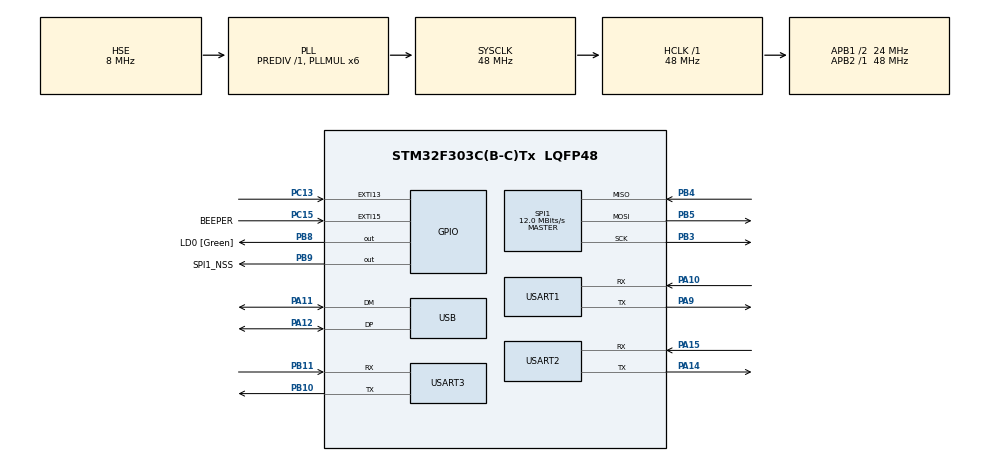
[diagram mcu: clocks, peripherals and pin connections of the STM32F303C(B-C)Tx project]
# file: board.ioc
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Mcu.Family=STM32F3
Mcu.Name=STM32F303C(B-C)Tx
Mcu.Package=LQFP48
NVIC.PriorityGroup=NVIC_PRIORITYGROUP_4
NVIC.USB_LP_CAN_RX0_IRQn=true\:0\:0\:false\:false\:true\:false
PA0.Signal=S_TIM2_CH1_ETR
PA1.Signal=S_TIM2_CH2
PA10.Mode=Asynchronous
PA10.Signal=USART1_RX
PA11.Mode=Device
PA11.Signal=USB_DM
PA12.Mode=Device
PA12.Signal=USB_DP
PA14.Mode=Asynchronous
PA14.Signal=USART2_TX
PA15.Mode=Asynchronous
PA15.Signal=USART2_RX
PA2.Signal=S_TIM2_CH3
PA3.Signal=S_TIM2_CH4
PA9.Mode=Asynchronous
PA9.Signal=USART1_TX
PB10.Mode=Asynchronous
PB10.Signal=USART3_TX
PB11.Mode=Asynchronous
PB11.Signal=USART3_RX
PB3.Mode=Full_Duplex_Master
PB3.Signal=SPI1_SCK
PB4.Mode=Full_Duplex_Master
PB4.Signal=SPI1_MISO
PB5.Mode=Full_Duplex_Master
PB5.Signal=SPI1_MOSI
PB8.GPIO_Label=LD0 [Green]
PB8.Signal=GPIO_Output
PB9.GPIO_Label=SPI1_NSS
PB9.Signal=GPIO_Output
PC13.Signal=GPXTI13
PC15-OSC32_OUT.GPIO_Label=BEEPER
PC15-OSC32_OUT.Signal=GPXTI15
PF0-OSC_IN.Mode=HSE-External-Oscillator
PF0-OSC_IN.Signal=RCC_OSC_IN
PF1-OSC_OUT.Mode=HSE-External-Oscillator
PF1-OSC_OUT.Signal=RCC_OSC_OUT
ProjectManager.HeapSize=0x200
ProjectManager.StackSize=0x400
ProjectManager.TargetToolchain=Makefile
RCC.AHBFreq_Value=48000000
RCC.APB1CLKDivider=RCC_HCLK_DIV2
RCC.APB1Freq_Value=24000000
RCC.APB1TimFreq_Value=48000000
RCC.APB2Freq_Value=48000000
RCC.APB2TimFreq_Value=48000000
RCC.CortexFreq_Value=48000000
RCC.HCLKFreq_Value=48000000
RCC.HSE_VALUE=8000000
RCC.HSI_VALUE=8000000
RCC.LSE_VALUE=32768
RCC.PLLMUL=RCC_PLL_MUL6
RCC.SYSCLKFreq_VALUE=48000000
RCC.SYSCLKSourceVirtual=RCC_SYSCLKSOURCE_PLLCLK
RCC.USBFreq_Value=48000000
SH.S_TIM2_CH1_ETR.0=TIM2_CH1
SH.S_TIM2_CH2.0=TIM2_CH2
SH.S_TIM2_CH3.0=TIM2_CH3
SH.S_TIM2_CH4.0=TIM2_CH4
SPI1.BaudRatePrescaler=SPI_BAUDRATEPRESCALER_4
SPI1.CalculateBaudRate=12.0 MBits/s
SPI1.Direction=SPI_DIRECTION_2LINES
SPI1.Mode=SPI_MODE_MASTER
SPI1.VirtualType=VM_MASTER
USART1.VirtualMode-Asynchronous=VM_ASYNC
USART2.VirtualMode-Asynchronous=VM_ASYNC
USART3.VirtualMode-Asynchronous=VM_ASYNC
USB_DEVICE.CLASS_NAME_FS=CDC
USB_DEVICE.VirtualMode=Cdc
USB_DEVICE.VirtualModeFS=Cdc_FS
VP_USB_DEVICE_VS_USB_DEVICE_CDC_FS.Mode=CDC_FS
board=board

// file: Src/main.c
/**
  ******************************************************************************
  * File Name          : main.c
  * Description        : Main program body
  ******************************************************************************
  * This notice applies to any and all portions of this file
  * that are not between comment pairs USER CODE BEGIN and
  * USER CODE END. Other portions of this file, whether
  * inserted by the user or by software development tools
  * are owned by their respective copyright owners.
  *
  * Copyright (c) 2018 STMicroelectronics International N.V.
  * All rights reserved.
  *
  * Redistribution and use in source and binary forms, with or without
  * modification, are permitted, provided that the following conditions are met:
  *
  * 1. Redistribution of source code must retain the above copyright notice,
  *    this list of conditions and the following disclaimer.
  * 2. Redistributions in binary form must reproduce the above copyright notice,
  *    this list of conditions and the following disclaimer in the documentation
  *    and/or other materials provided with the distribution.
  * 3. Neither the name of STMicroelectronics nor the names of other
  *    contributors to this software may be used to endorse or promote products
  *    derived from this software without specific written permission.
  * 4. This software, including modifications and/or derivative works of this
  *    software, must execute solely and exclusively on microcontroller or
  *    microprocessor devices manufactured by or for STMicroelectronics.
  * 5. Redistribution and use of this software other than as permitted under
  *    this license is void and will automatically terminate your rights under
  *    this license.
  *
  * THIS SOFTWARE IS PROVIDED BY STMICROELECTRONICS AND CONTRIBUTORS "AS IS"
  * AND ANY EXPRESS, IMPLIED OR STATUTORY WARRANTIES, INCLUDING, BUT NOT
  * LIMITED TO, THE IMPLIED WARRANTIES OF MERCHANTABILITY, FITNESS FOR A
  * PARTICULAR PURPOSE AND NON-INFRINGEMENT OF THIRD PARTY INTELLECTUAL PROPERTY
  * RIGHTS ARE DISCLAIMED TO THE FULLEST EXTENT PERMITTED BY LAW. IN NO EVENT
  * SHALL STMICROELECTRONICS OR CONTRIBUTORS BE LIABLE FOR ANY DIRECT, INDIRECT,
  * INCIDENTAL, SPECIAL, EXEMPLARY, OR CONSEQUENTIAL DAMAGES (INCLUDING, BUT NOT
  * LIMITED TO, PROCUREMENT OF SUBSTITUTE GOODS OR SERVICES; LOSS OF USE, DATA,
  * OR PROFITS; OR BUSINESS INTERRUPTION) HOWEVER CAUSED AND ON ANY THEORY OF
  * LIABILITY, WHETHER IN CONTRACT, STRICT LIABILITY, OR TORT (INCLUDING
  * NEGLIGENCE OR OTHERWISE) ARISING IN ANY WAY OUT OF THE USE OF THIS SOFTWARE,
  * EVEN IF ADVISED OF THE POSSIBILITY OF SUCH DAMAGE.
  *
  ******************************************************************************
  */
#include "main.h"
#include "stm32f3xx_hal.h"
#include "spi.h"
#include "usart.h"
#include "usb_device.h"
#include "gpio.h"

/* USER CODE BEGIN PV */
/* Private variables ---------------------------------------------------------*/

/* USER CODE END PV */

void SystemClock_Config(void);

/* USER CODE BEGIN PFP */
/* Private function prototypes -----------------------------------------------*/

/* USER CODE END PFP */

int main(void)
{

  /* MCU Configuration----------------------------------------------------------*/

  /* Reset of all peripherals, Initializes the Flash interface and the Systick. */
  HAL_Init();

  /* Configure the system clock */
  SystemClock_Config();

  /* Initialize all configured peripherals */
  MX_GPIO_Init();
  MX_USART1_UART_Init();
  MX_USART2_UART_Init();
  MX_USART3_UART_Init();
  MX_SPI1_Init();
  MX_USB_DEVICE_Init();

  /* Infinite loop */
  while (1)
  {

  /* USER CODE BEGIN 3 */
    HAL_GPIO_TogglePin(LD0_GPIO_Port, LD0_Pin);
    HAL_Delay(3000);
  }
  /* USER CODE END 3 */

}

/** System Clock Configuration
*/
void SystemClock_Config(void)
{

  RCC_OscInitTypeDef RCC_OscInitStruct;
  RCC_ClkInitTypeDef RCC_ClkInitStruct;
  RCC_PeriphCLKInitTypeDef PeriphClkInit;

    /**Initializes the CPU, AHB and APB busses clocks
    */
  RCC_OscInitStruct.OscillatorType = RCC_OSCILLATORTYPE_HSE;
  RCC_OscInitStruct.HSEState = RCC_HSE_ON;
  RCC_OscInitStruct.HSEPredivValue = RCC_HSE_PREDIV_DIV1;
  RCC_OscInitStruct.HSIState = RCC_HSI_ON;
  RCC_OscInitStruct.PLL.PLLState = RCC_PLL_ON;
  RCC_OscInitStruct.PLL.PLLSource = RCC_PLLSOURCE_HSE;
  RCC_OscInitStruct.PLL.PLLMUL = RCC_PLL_MUL6;
  if (HAL_RCC_OscConfig(&RCC_OscInitStruct) != HAL_OK)
  {
    _Error_Handler(__FILE__, __LINE__);
  }

    /**Initializes the CPU, AHB and APB busses clocks
    */
  RCC_ClkInitStruct.ClockType = RCC_CLOCKTYPE_HCLK|RCC_CLOCKTYPE_SYSCLK
                              |RCC_CLOCKTYPE_PCLK1|RCC_CLOCKTYPE_PCLK2;
  RCC_ClkInitStruct.SYSCLKSource = RCC_SYSCLKSOURCE_PLLCLK;
  RCC_ClkInitStruct.AHBCLKDivider = RCC_SYSCLK_DIV1;
  RCC_ClkInitStruct.APB1CLKDivider = RCC_HCLK_DIV2;
  RCC_ClkInitStruct.APB2CLKDivider = RCC_HCLK_DIV1;

  if (HAL_RCC_ClockConfig(&RCC_ClkInitStruct, FLASH_LATENCY_1) != HAL_OK)
  {
    _Error_Handler(__FILE__, __LINE__);
  }

  PeriphClkInit.PeriphClockSelection = RCC_PERIPHCLK_USB|RCC_PERIPHCLK_USART1
                              |RCC_PERIPHCLK_USART2|RCC_PERIPHCLK_USART3;
  PeriphClkInit.Usart1ClockSelection = RCC_USART1CLKSOURCE_PCLK2;
  PeriphClkInit.Usart2ClockSelection = RCC_USART2CLKSOURCE_PCLK1;
  PeriphClkInit.Usart3ClockSelection = RCC_USART3CLKSOURCE_PCLK1;
  PeriphClkInit.USBClockSelection = RCC_USBCLKSOURCE_PLL;
  if (HAL_RCCEx_PeriphCLKConfig(&PeriphClkInit) != HAL_OK)
  {
    _Error_Handler(__FILE__, __LINE__);
  }

    /**Configure the Systick interrupt time
    */
  HAL_SYSTICK_Config(HAL_RCC_GetHCLKFreq()/1000);

    /**Configure the Systick
    */
  HAL_SYSTICK_CLKSourceConfig(SYSTICK_CLKSOURCE_HCLK);

  /* SysTick_IRQn interrupt configuration */
  HAL_NVIC_SetPriority(SysTick_IRQn, 0, 0);
}

void _Error_Handler(char * file, int line)
{
  while(1)
  {
  }
}

/************************ (C) COPYRIGHT STMicroelectronics *****END OF FILE****/
